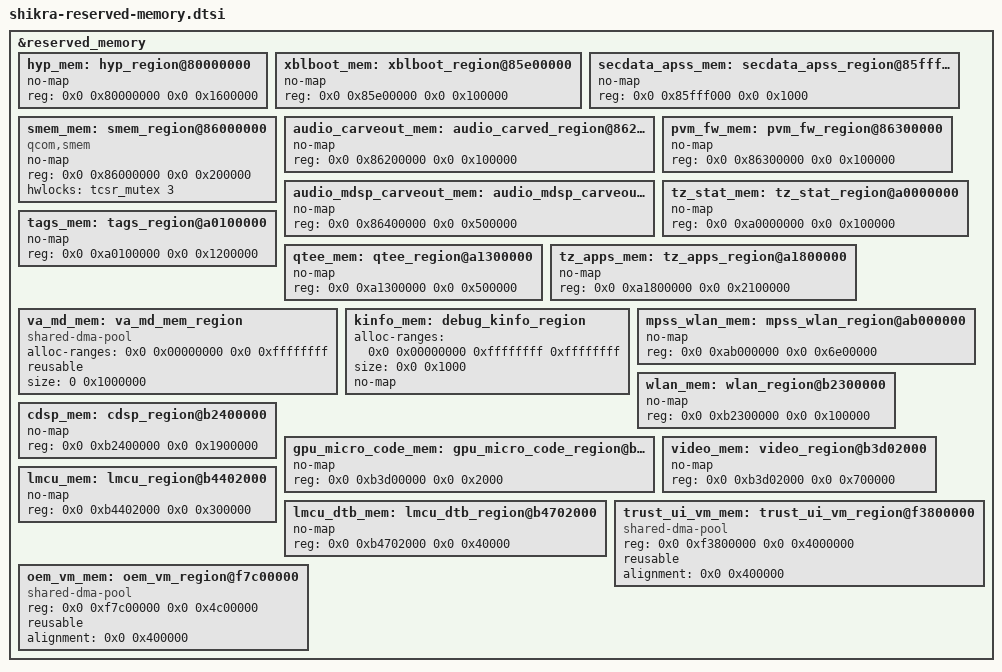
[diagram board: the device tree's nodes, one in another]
// SPDX-License-Identifier: BSD-3-Clause
/*
 * Copyright (c) Qualcomm Technologies, Inc. and/or its subsidiaries.
 */

&reserved_memory {
	#address-cells = <2>;
	#size-cells = <2>;
	ranges;

	hyp_mem: hyp_region@80000000 {
		no-map;
		reg = <0x0 0x80000000 0x0 0x1600000>;
	};

	xblboot_mem: xblboot_region@85e00000 {
		no-map;
		reg = <0x0 0x85e00000 0x0 0x100000>;
	};

	secdata_apss_mem: secdata_apss_region@85fff000 {
		no-map;
		reg = <0x0 0x85fff000 0x0 0x1000>;
	};

	smem_mem: smem_region@86000000 {
		compatible = "qcom,smem";
		no-map;
		reg = <0x0 0x86000000 0x0 0x200000>;
		hwlocks = <&tcsr_mutex 3>;
	};

	audio_carveout_mem: audio_carved_region@86200000 {
		no-map;
		reg = <0x0 0x86200000 0x0 0x100000>;
	};

	pvm_fw_mem: pvm_fw_region@86300000 {
		no-map;
		reg = <0x0 0x86300000 0x0 0x100000>;
	};

	audio_mdsp_carveout_mem: audio_mdsp_carveout_region@86400000 {
		no-map;
		reg = <0x0 0x86400000 0x0 0x500000>;
	};

	/* UEFI region at 0x9F400000 is reclaimed by Linux */
	tz_stat_mem: tz_stat_region@a0000000 {
		no-map;
		reg = <0x0 0xa0000000 0x0 0x100000>;
	};

	tags_mem: tags_region@a0100000 {
		no-map;
		reg = <0x0 0xa0100000 0x0 0x1200000>;
	};

	qtee_mem: qtee_region@a1300000 {
		no-map;
		reg = <0x0 0xa1300000 0x0 0x500000>;
	};

	tz_apps_mem: tz_apps_region@a1800000 {
		no-map;
		reg = <0x0 0xa1800000 0x0 0x2100000>;
	};

	va_md_mem: va_md_mem_region {
		compatible = "shared-dma-pool";
		alloc-ranges = <0x0 0x00000000 0x0 0xffffffff>;
		reusable;
		size = <0 0x1000000>;
	};

	kinfo_mem: debug_kinfo_region {
		alloc-ranges = <0x0 0x00000000 0xffffffff 0xffffffff>;
		size = <0x0 0x1000>;
		no-map;
	};

	mpss_wlan_mem: mpss_wlan_region@ab000000 {
		no-map;
		reg = <0x0 0xab000000 0x0 0x6e00000>;
	};

	wlan_mem: wlan_region@b2300000 {
		no-map;
		reg = <0x0 0xb2300000 0x0 0x100000>;
	};

	cdsp_mem: cdsp_region@b2400000 {
		no-map;
		reg = <0x0 0xb2400000 0x0 0x1900000>;
	};

	gpu_micro_code_mem: gpu_micro_code_region@b3d00000 {
		no-map;
		reg = <0x0 0xb3d00000 0x0 0x2000>;
	};

	video_mem: video_region@b3d02000 {
		no-map;
		reg = <0x0 0xb3d02000 0x0 0x700000>;
	};

	lmcu_mem: lmcu_region@b4402000 {
		no-map;
		reg = <0x0 0xb4402000 0x0 0x300000>;
	};

	lmcu_dtb_mem: lmcu_dtb_region@b4702000 {
		no-map;
		reg = <0x0 0xb4702000 0x0 0x40000>;
	};

	/* Linux kernel image is loaded at 0xB5000000 */
	trust_ui_vm_mem: trust_ui_vm_region@f3800000 {
		compatible = "shared-dma-pool";
		reg = <0x0 0xf3800000 0x0 0x4000000>;
		reusable;
		alignment = <0x0 0x400000>;
	};

	oem_vm_mem: oem_vm_region@f7c00000 {
		compatible = "shared-dma-pool";
		reg = <0x0 0xf7c00000 0x0 0x4c00000>;
		reusable;
		alignment = <0x0 0x400000>;
	};
};

